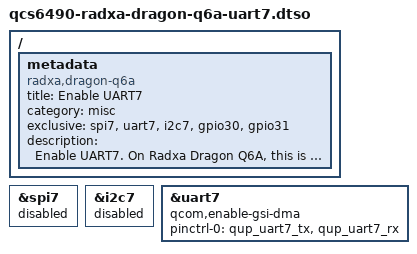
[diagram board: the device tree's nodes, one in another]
// SPDX-License-Identifier: BSD-3-Clause
/*
 * Copyright (c) 2026 Radxa Computer (Shenzhen) Co., Ltd.
 */

/dts-v1/;
/plugin/;

/ {
	metadata {
		title = "Enable UART7";
		compatible = "radxa,dragon-q6a";
		category = "misc";
		exclusive = "spi7", "uart7", "i2c7", "gpio30", "gpio31";
		description = "Enable UART7.
On Radxa Dragon Q6A, this is pin 32(tx), 29(rx).";
	};
};

&spi7 {
	status = "disabled";
};

&i2c7 {
	status = "disabled";
};

&uart7 {
	qcom,enable-gsi-dma;
	status = "okay";
	pinctrl-0 = <&qup_uart7_tx>, <&qup_uart7_rx>;
};
